# RSL15 register map
Vendor: ONSemiconductor; Series: RSL15 Series; File version: 1.0
CPU: CM33 r0p4, little endian, MPU, FPU, 3 interrupt priority bits
Registers are 32-bit, read-write, reset 0x0 unless marked. A register's access mark holds for its fields unless they carry their own. Offsets are from the block's base; [hi:lo] are bit positions; {n}, {i} and the like mark numbered series.

## DMA0 — DMA Controller
Base 0x40001200
Same registers: DMA1 0x40001300, DMA2 0x40001400, DMA3 0x40001500
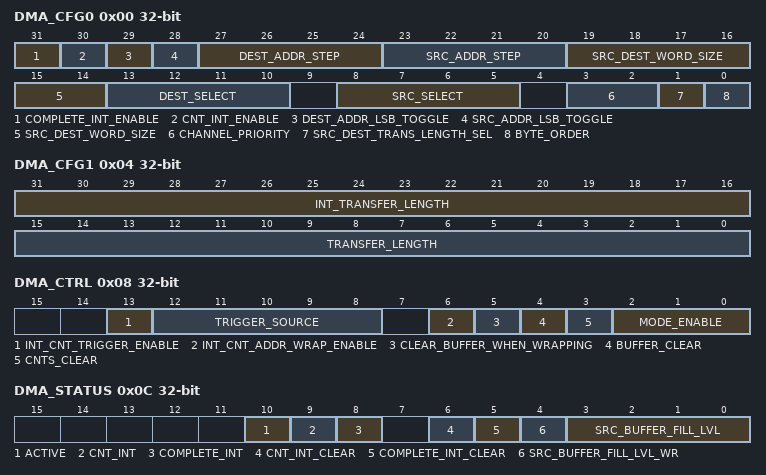
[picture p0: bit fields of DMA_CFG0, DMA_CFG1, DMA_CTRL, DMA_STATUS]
0x00 DMA_CFG0 — DMA Channel Configuration Register
  [31] COMPLETE_INT_ENABLE — Raise an interrupt when the DMA transfer completes
    0=DMA_COMPLETE_INT_DISABLE (Disable completion interrupts for DMA channel); 1=DMA_COMPLETE_INT_ENABLE (Enable completion interrupts for DMA channel)
  [30] CNT_INT_ENABLE — Raise an interrupt when the DMA transfer reaches the counter value
    0=DMA_CNT_INT_DISABLE (Disable counter interrupts for DMA channel); 1=DMA_CNT_INT_ENABLE (Enable counter interrupts for DMA channel)
  [29] DEST_ADDR_LSB_TOGGLE — Enable an address LSB toggling for the destination
    0=DMA_DEST_ADDR_LSB_TOGGLE_DISABLE (No toggling on the destination address LSB); 1=DMA_DEST_ADDR_LSB_TOGGLE_ENABLE (Toggle the destination address LSB)
  [28] SRC_ADDR_LSB_TOGGLE — Enable an address LSB toggling for the source
    0=DMA_SRC_ADDR_LSB_TOGGLE_DISABLE (No toggling on the source address LSB); 1=DMA_SRC_ADDR_LSB_TOGGLE_ENABLE (Toggle the source address LSB)
  [27:24] DEST_ADDR_STEP — Configure whether the destination address increments/decrements in terms of destination word size
    0=DMA_DEST_ADDR_STATIC (Do not increment the destination address used by DMA channel); {v}=DMA_DEST_ADDR_INCR_{v} (Set the step size of DMA channel destination address to {v}) (v=1..7); 8=DMA_DEST_ADDR_DECR_8 (Set the step size of DMA channel destination address to minus 8); 9=DMA_DEST_ADDR_DECR_7 (Set the step size of DMA channel destination address to minus 7); 10=DMA_DEST_ADDR_DECR_6 (Set the step size of DMA channel destination address to minus 6); 11=DMA_DEST_ADDR_DECR_5 (Set the step size of DMA channel destination address to minus 5); 12=DMA_DEST_ADDR_DECR_4 (Set the step size of DMA channel destination address to minus 4); 13=DMA_DEST_ADDR_DECR_3 (Set the step size of DMA channel destination address to minus 3); 14=DMA_DEST_ADDR_DECR_2 (Set the step size of DMA channel destination address to minus 2); 15=DMA_DEST_ADDR_DECR_1 (Set the step size of DMA channel destination address to minus 1)
  [23:20] SRC_ADDR_STEP — Configure whether the source address increments/decrements in terms of source word size
    0=DMA_SRC_ADDR_STATIC (Do not increment the source address used by DMA channel); {v}=DMA_SRC_ADDR_INCR_{v} (Set the step size of DMA channel source address to {v}) (v=1..7); 8=DMA_SRC_ADDR_DECR_8 (Set the step size of DMA channel source address to minus 8); 9=DMA_SRC_ADDR_DECR_7 (Set the step size of DMA channel source address to minus 7); 10=DMA_SRC_ADDR_DECR_6 (Set the step size of DMA channel source address to minus 6); 11=DMA_SRC_ADDR_DECR_5 (Set the step size of DMA channel source address to minus 5); 12=DMA_SRC_ADDR_DECR_4 (Set the step size of DMA channel source address to minus 4); 13=DMA_SRC_ADDR_DECR_3 (Set the step size of DMA channel source address to minus 3); 14=DMA_SRC_ADDR_DECR_2 (Set the step size of DMA channel source address to minus 2); 15=DMA_SRC_ADDR_DECR_1 (Set the step size of DMA channel source address to minus 1)
  [19:14] SRC_DEST_WORD_SIZE — Select the source and destination word sizes for the transfer
    0=WORD_SIZE_32BITS_TO_32BITS (source data uses 32-bit word and destination data uses 32-bit word); 1=WORD_SIZE_32BITS_TO_4BITS (source data uses 32-bit word and destination data uses 4-bit word); 2=WORD_SIZE_32BITS_TO_8BITS (source data uses 32-bit word and destination data uses 8-bit word); 4=WORD_SIZE_32BITS_TO_16BITS (source data uses 32-bit word and destination data uses 16-bit word); 8=WORD_SIZE_4BITS_TO_32BITS (source data uses 4-bit word and destination data uses 32-bit word); 9=WORD_SIZE_4BITS_TO_4BITS (source data uses 4-bit word and destination data uses 4-bit word); 10=WORD_SIZE_4BITS_TO_8BITS (source data uses 4-bit word and destination data uses 8-bit word); 12=WORD_SIZE_4BITS_TO_16BITS (source data uses 4-bit word and destination data uses 16-bit word); 16=WORD_SIZE_8BITS_TO_32BITS (source data uses 8-bit word and destination data uses 32-bit word); 17=WORD_SIZE_8BITS_TO_4BITS (source data uses 8-bit word and destination data uses 4-bit word); 18=WORD_SIZE_8BITS_TO_8BITS (source data uses 8-bit word and destination data uses 8-bit word); 20=WORD_SIZE_8BITS_TO_16BITS (source data uses 8-bit word and destination data uses 16-bit word); 32=WORD_SIZE_16BITS_TO_32BITS (source data uses 16-bit word and destination data uses 32-bit word); 33=WORD_SIZE_16BITS_TO_4BITS (source data uses 16-bit word and destination data uses 4-bit word); 34=WORD_SIZE_16BITS_TO_8BITS (source data uses 16-bit word and destination data uses 8-bit word); 36=WORD_SIZE_16BITS_TO_16BITS (source data uses 16-bit word and destination data uses 16-bit word)
  [13:10] DEST_SELECT — Select the request line for the destination
    0=DMA_DEST_ALWAYS_ON (Data writes are always triggered); 1=DMA_DEST_SPI0 (Data writes are triggered by the SPI0 request line); 2=DMA_DEST_SPI1 (Data writes are triggered by the SPI1 request line); 3=DMA_DEST_I2C0 (Data writes are triggered by the I2C0 request line); 4=DMA_DEST_I2C1 (Data writes are triggered by the I2C1 request line); 5=DMA_DEST_UART0 (Data writes are triggered by the UART0 request line); 6=DMA_DEST_PCM0 (Data writes are triggered by the PCM0 request line); 7=DMA_DEST_TOF (Data writes are triggered by the TOF request line); {v}=DMA_DEST_NOT_USED_{v} (Data writes are triggered by the DEST_NOT_USED_{v} request line) (v=8..15)
  [8:5] SRC_SELECT — Select the request line for the source
    0=DMA_SRC_ALWAYS_ON (Data reads are always triggered); 1=DMA_SRC_SPI0 (Data reads are triggered by the SPI0 request line); 2=DMA_SRC_SPI1 (Data reads are triggered by the SPI1 request line); 3=DMA_SRC_I2C0 (Data reads are triggered by the I2C0 request line); 4=DMA_SRC_I2C1 (Data reads are triggered by the I2C1 request line); 5=DMA_SRC_UART0 (Data reads are triggered by the UART0 request line); 6=DMA_SRC_PCM0 (Data reads are triggered by the PCM0 request line); 7=DMA_SRC_TOF (Data reads are triggered by the TOF request line); 8=DMA_SRC_RF_IQ_READY (Data reads are triggered by the RF_IQ_READY request line); 9=DMA_SRC_RF_PHASE_ADC_READY (Data reads are triggered by the RF_PHASE_ADC_READY request line); {v}=DMA_SRC_NOT_USED_{v} (Data reads are triggered by the SRC_NOT_USED_{v} request line) (v=10..15)
  [3:2] CHANNEL_PRIORITY — Select the priority level for this channel
    0=DMA_PRIORITY_0 (Set the priority of DMA channel to 0 (Lowest)); 1=DMA_PRIORITY_1 (Set the priority of DMA channel to 1); 2=DMA_PRIORITY_2 (Set the priority of DMA channel to 2); 3=DMA_PRIORITY_3 (Set the priority of DMA channel to 3 (highest))
  [1] SRC_DEST_TRANS_LENGTH_SEL — Selects whether the transfer length counter depends on either the source word counts or the destination word count
    0=DEST_TRANS_LENGTH_SEL (Transfer length counter depends on the destination word count); 1=SRC_TRANS_LENGTH_SEL (Transfer length counter depends on the source word count)
  [0] BYTE_ORDER — Select the byte ordering of the DMA channel
    0=DMA_LITTLE_ENDIAN (DMA channel uses little endian mode); 1=DMA_BIG_ENDIAN (DMA channel uses big endian mode)
0x04 DMA_CFG1 — DMA Channel Transfer Configuration Register
  [31:16] INT_TRANSFER_LENGTH — Trigger a counter interrupt when the DMA transfer word count reaches this value
  [15:0] TRANSFER_LENGTH — The length, in words, of each data transfer using DMA channel
0x08 DMA_CTRL (reset mask 0x3F67) — DMA Channel Control
  [13] INT_CNT_TRIGGER_ENABLE — Enable waiting on a trigger when an interrupt counter event occurs
    0=DMA_INT_CNT_TRIGGER_DISABLE (The DMA channel does not pause when an interrupt counter event occurs); 1=DMA_INT_CNT_TRIGGER_ENABLE (The DMA channel pauses when an interrupt counter event occurs and waits for a trigger source event to continue)
  [12:8] TRIGGER_SOURCE — Selects which event triggers this DMA channel when triggering is enabled
    {v}=DMA_CH{v}_COMPLETED (This DMA channel is triggered when CH{v}_COMPLETED occurs) (v=0..3); 4=DMA_SENSOR (This DMA channel is triggered when SENSOR occurs); 5=DMA_LIN_RX (This DMA channel is triggered when LIN_RX occurs); 6=DMA_SAR (This DMA channel is triggered when SAR occurs); {v}=DMA_TIMER{v-7} (This DMA channel is triggered when TIMER{v-7} occurs) (v=7..10); {v}=DMA_TRIGGER_NOT_USED_{v} (This DMA channel is triggered when TRIGGER_NOT_USED_{v} occurs) (v=11..31)
  [6] INT_CNT_ADDR_WRAP_ENABLE — Enable source or destination (depending on SRC_DEST_TRANS_LENGTH_SEL) address wrapping when an interrupt counter event occurs
    0=DMA_INT_CNT_ADDR_WRAP_DISABLE (Source address and destination addresses are wrapped normally); 1=DMA_INT_CNT_ADDR_WRAP_ENABLE (When the interrupt counter is reached, source or destination address is wrapped depending on SRC_DEST_TRANS_LENGTH_SEL)
  [5] CLEAR_BUFFER_WHEN_WRAPPING — Clear buffer during address wrapping
    0=DMA_KEEP_BUFFER_WHEN_WRAPPING (Buffer contents are not cleared during address wrapping); 1=DMA_CLEAR_BUFFER_WHEN_WRAPPING (Buffer contents are cleared during address wrapping)
  [4] BUFFER_CLEAR wo — Clear source buffer
    1=DMA_CLEAR_BUFFER (Clears the DMA source buffered data)
  [3] CNTS_CLEAR wo — Clear counters
    1=DMA_CLEAR_CNTS (Clears the DMA counters)
  [2:0] MODE_ENABLE — Enable mode of operation of the DMA Channel
    0=DMA_DISABLE (Disable DMA channel (channel waits on current READ or WRITE access to finish before the active bit is cleared)); 1=DMA_ENABLE (Enable DMA channel and when completed disable); 2=DMA_ENABLE_WRAP (Enable DMA channel and when completed, wrap addresses and disable); 3=DMA_ENABLE_WRAP_RESTART (Enable DMA channel and when completed, wrap addresses and restart); 4=DMA_TRIGGER (When source trigger occurs enable DMA channel, when completed disable); 5=DMA_TRIGGER_WRAP (When source trigger occurs enable DMA channel, when completed wrap addresses and disable); 6=DMA_TRIGGER_WRAP_RESTART (When source trigger occurs enable DMA channel, when completed wrap addresses and restart); 7=DMA_TRIGGER_WRAP_TRIGGER_RESTART (When source trigger occurs enable DMA channel, when completed wrap addresses, and upon next trigger event restart)
0x0C DMA_STATUS (reset mask 0x70F) — DMA Channel Status
  [10] ACTIVE ro — Active status of the channel
    0=DMA_NON_ACTIVE (DMA channel is disabled or waiting for a trigger event.); 1=DMA_ACTIVE (DMA channel is running)
  [9] CNT_INT ro — Indicate if a counter interrupt has occurred on DMA channel
    0=DMA_CNT_INT_FALSE (Indicate that no counter interrupt has occurred); 1=DMA_CNT_INT_TRUE (Indicate that a counter interrupt has occurred)
  [8] COMPLETE_INT ro — Indicate if a complete interrupt has occurred on DMA channel
    0=DMA_COMPLETE_INT_FALSE (Indicate that a no complete interrupt has occurred); 1=DMA_COMPLETE_INT_TRUE (Indicate that a complete interrupt has occurred)
  [6] CNT_INT_CLEAR wo — Clear the counter interrupt flag
    1=DMA_CNT_INT_CLEAR (Clear the counter interrupt flag)
  [5] COMPLETE_INT_CLEAR wo — Clear the complete interrupt flag
    1=DMA_COMPLETE_INT_CLEAR (Clear the complete interrupt flag)
  [4] SRC_BUFFER_FILL_LVL_WR wo — Enable writing of SRC_BUFFER_FILL_LVL
    1=DMA_SRC_BUFFER_FILL_LVL_WR (Enable writing of SRC_BUFFER_FILL_LVL)
  [3:0] SRC_BUFFER_FILL_LVL — The number of nibbles currently in the source buffer (0: buffer is empty, 8: the 32-bit buffer is completely full)
0x10 DMA_SRC_ADDR — DMA Channel Source Address
  [31:0] SRC_ADDR — Address for the source of data transferred using DMA channel
0x14 DMA_DEST_ADDR — DMA Channel Destination Address
  [31:0] DEST_ADDR — Address for the destination of data transferred using DMA channel
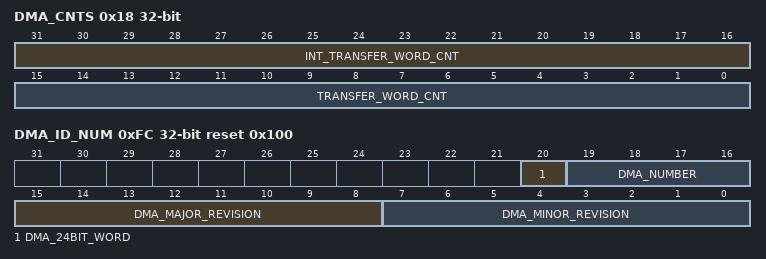
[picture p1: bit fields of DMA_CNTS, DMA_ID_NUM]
0x18 DMA_CNTS — DMA Channel Counters
  [31:16] INT_TRANSFER_WORD_CNT — Interrupt word counter (automatically reset after each counter interrupt)
  [15:0] TRANSFER_WORD_CNT — The number of words that have been transferred using DMA channel during the current transfer
0x1C DMA_SRC_BUFFER — DMA Channel Source buffered data after packing
  [31:0] SRC_BUFFER — Packed word which has been read from the source addresses.
0xFC DMA_ID_NUM ro reset 0x100 — DMA ID number
  [20] DMA_24BIT_WORD — 24-bit word size supported
    0=DMA_24BIT_WORD_NOT_SUPPORTED (24-bit word size not supported); 1=DMA_24BIT_WORD_SUPPORTED (24-bit word size supported)
  [19:16] DMA_NUMBER — DMA channel number
  [15:8] DMA_MAJOR_REVISION — DMA Major Revision number
    1=DMA_MAJOR_REVISION (DMA revision 1.0)
  [7:0] DMA_MINOR_REVISION — DMA Minor Revision number
    0=DMA_MINOR_REVISION (DMA revision 1.0)
